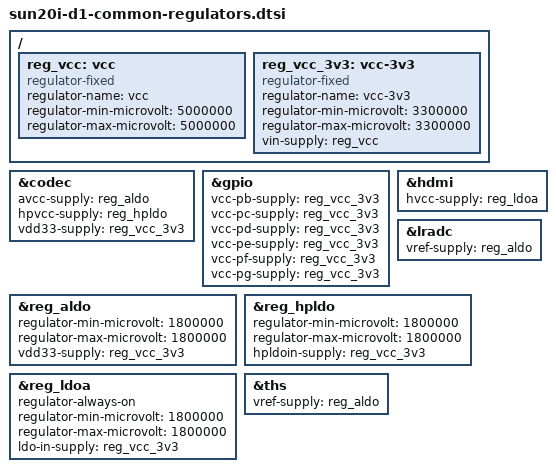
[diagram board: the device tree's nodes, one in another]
/*
 * Copyright (C) 2022 Samuel Holland <samuel@sholland.org>
 *
 * This file is dual-licensed: you can use it either under the terms
 * of the GPL-2.0+ or the MIT license, at your option. Note that this dual
 * licensing only applies to this file, and not this project as a
 * whole.
 *
 *  a) This file is free software; you can redistribute it and/or
 *     modify it under the terms of the GNU General Public License as
 *     published by the Free Software Foundation; either version 2 of the
 *     License, or (at your option) any later version.
 *
 *     This file is distributed in the hope that it will be useful,
 *     but WITHOUT ANY WARRANTY; without even the implied warranty of
 *     MERCHANTABILITY or FITNESS FOR A PARTICULAR PURPOSE.  See the
 *     GNU General Public License for more details.
 *
 * Or, alternatively,
 *
 *  b) Permission is hereby granted, free of charge, to any person
 *     obtaining a copy of this software and associated documentation
 *     files (the "Software"), to deal in the Software without
 *     restriction, including without limitation the rights to use,
 *     copy, modify, merge, publish, distribute, sublicense, and/or
 *     sell copies of the Software, and to permit persons to whom the
 *     Software is furnished to do so, subject to the following
 *     conditions:
 *
 *     The above copyright notice and this permission notice shall be
 *     included in all copies or substantial portions of the Software.
 *
 *     THE SOFTWARE IS PROVIDED "AS IS", WITHOUT WARRANTY OF ANY KIND,
 *     EXPRESS OR IMPLIED, INCLUDING BUT NOT LIMITED TO THE WARRANTIES
 *     OF MERCHANTABILITY, FITNESS FOR A PARTICULAR PURPOSE AND
 *     NONINFRINGEMENT. IN NO EVENT SHALL THE AUTHORS OR COPYRIGHT
 *     HOLDERS BE LIABLE FOR ANY CLAIM, DAMAGES OR OTHER LIABILITY,
 *     WHETHER IN AN ACTION OF CONTRACT, TORT OR OTHERWISE, ARISING
 *     FROM, OUT OF OR IN CONNECTION WITH THE SOFTWARE OR THE USE OR
 *     OTHER DEALINGS IN THE SOFTWARE.
 */

/ {
	reg_vcc: vcc {
		compatible = "regulator-fixed";
		regulator-name = "vcc";
		regulator-min-microvolt = <5000000>;
		regulator-max-microvolt = <5000000>;
	};

	reg_vcc_3v3: vcc-3v3 {
		compatible = "regulator-fixed";
		regulator-name = "vcc-3v3";
		regulator-min-microvolt = <3300000>;
		regulator-max-microvolt = <3300000>;
		vin-supply = <&reg_vcc>;
	};
};

&codec {
	avcc-supply = <&reg_aldo>;
	hpvcc-supply = <&reg_hpldo>;
	vdd33-supply = <&reg_vcc_3v3>;
};

&gpio {
	vcc-pb-supply = <&reg_vcc_3v3>;
	vcc-pc-supply = <&reg_vcc_3v3>;
	vcc-pd-supply = <&reg_vcc_3v3>;
	vcc-pe-supply = <&reg_vcc_3v3>;
	vcc-pf-supply = <&reg_vcc_3v3>;
	vcc-pg-supply = <&reg_vcc_3v3>;
};

&hdmi {
	hvcc-supply = <&reg_ldoa>;
};

&lradc {
	vref-supply = <&reg_aldo>;
};

&reg_aldo {
	regulator-min-microvolt = <1800000>;
	regulator-max-microvolt = <1800000>;
	vdd33-supply = <&reg_vcc_3v3>;
};

&reg_hpldo {
	regulator-min-microvolt = <1800000>;
	regulator-max-microvolt = <1800000>;
	hpldoin-supply = <&reg_vcc_3v3>;
};

&reg_ldoa {
	regulator-always-on;
	regulator-min-microvolt = <1800000>;
	regulator-max-microvolt = <1800000>;
	ldo-in-supply = <&reg_vcc_3v3>;
};

&ths {
	vref-supply = <&reg_aldo>;
};
